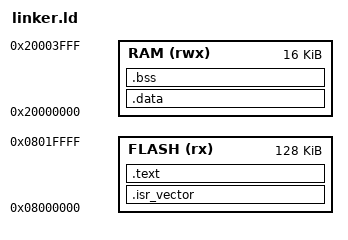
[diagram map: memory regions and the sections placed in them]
/* Minimal linker script - adjust lengths for your MCU */
ENTRY(Reset_Handler)

MEMORY
{
  FLASH (rx) : ORIGIN = 0x08000000, LENGTH = 128K
  RAM   (rwx) : ORIGIN = 0x20000000, LENGTH = 16K
}

_estack = ORIGIN(RAM) + LENGTH(RAM);

SECTIONS
{
  .isr_vector :
  {
    . = ALIGN(4);
    KEEP(*(.isr_vector))
  } > FLASH

  .text :
  {
    . = ALIGN(4);
    *(.text*)
    *(.rodata*)
    . = ALIGN(4);
  } > FLASH

  .data : AT(ADDR(.text) + SIZEOF(.text))
  {
    . = ALIGN(4);
    _sdata = .;
    *(.data*)
    . = ALIGN(4);
    _edata = .;
  } > RAM

  .bss :
  {
    . = ALIGN(4);
    _sbss = .;
    *(.bss*)
    *(COMMON)
    . = ALIGN(4);
    _ebss = .;
  } > RAM

  . = ALIGN(4);
  _heap_start = .;
  . = . + 0x200;
  _heap_end = .;

  PROVIDE(end = .);
}
